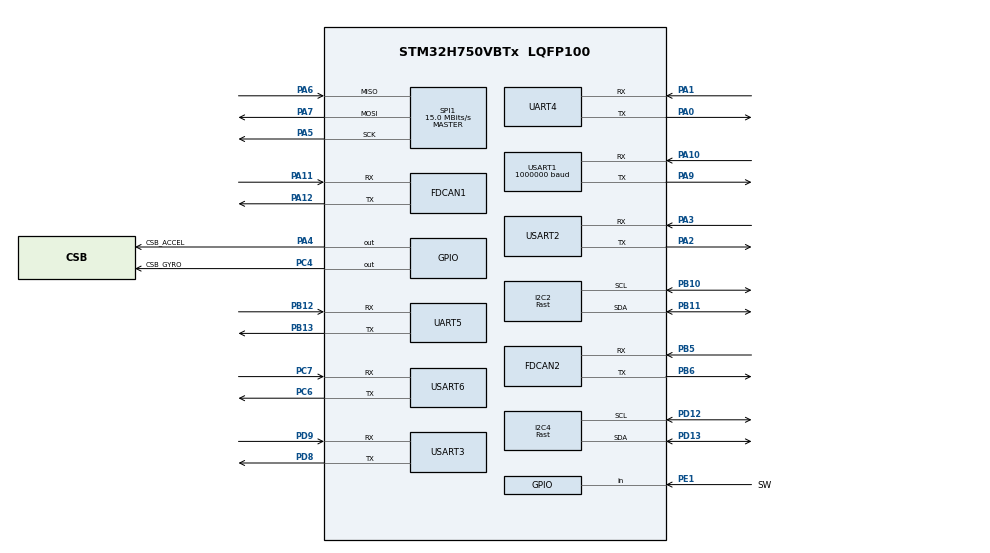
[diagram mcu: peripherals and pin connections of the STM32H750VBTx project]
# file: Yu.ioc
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CORTEX_M7.AccessPermission_Spec=MPU_REGION_FULL_ACCESS
CORTEX_M7.BaseAddress_Spec=0x24000000
CORTEX_M7.CPU_DCache=Enabled
CORTEX_M7.CPU_ICache=Enabled
CORTEX_M7.DisableExec_Spec=MPU_INSTRUCTION_ACCESS_ENABLE
CORTEX_M7.IsCacheable_Spec=MPU_ACCESS_CACHEABLE
CORTEX_M7.IsShareable_Spec=MPU_ACCESS_SHAREABLE
CORTEX_M7.MPU_Control=MPU_HFNMI_PRIVDEF
CORTEX_M7.Size_Spec=MPU_REGION_SIZE_512KB
CORTEX_M7.SubRegionDisable_Spec=0x0
CORTEX_M7.default_mode_Activation=1
Dma.Request0=UART5_RX
Dma.Request1=UART5_TX
Dma.Request10=USART6_TX
Dma.Request11=SPI1_RX
Dma.Request12=SPI1_TX
Dma.Request2=UART4_RX
Dma.Request3=UART4_TX
Dma.Request4=USART2_RX
Dma.Request5=USART2_TX
Dma.Request6=USART1_RX
Dma.Request7=USART3_RX
Dma.Request8=USART3_TX
Dma.Request9=USART6_RX
Dma.SPI1_RX.11.Direction=DMA_PERIPH_TO_MEMORY
Dma.SPI1_RX.11.EventEnable=DISABLE
Dma.SPI1_RX.11.FIFOMode=DMA_FIFOMODE_DISABLE
Dma.SPI1_RX.11.Instance=DMA2_Stream3
Dma.SPI1_RX.11.MemDataAlignment=DMA_MDATAALIGN_BYTE
Dma.SPI1_RX.11.MemInc=DMA_MINC_ENABLE
Dma.SPI1_RX.11.Mode=DMA_NORMAL
Dma.SPI1_RX.11.PeriphDataAlignment=DMA_PDATAALIGN_BYTE
Dma.SPI1_RX.11.PeriphInc=DMA_PINC_DISABLE
Dma.SPI1_RX.11.Polarity=HAL_DMAMUX_REQ_GEN_RISING
Dma.SPI1_RX.11.Priority=DMA_PRIORITY_LOW
Dma.SPI1_RX.11.RequestNumber=1
Dma.SPI1_RX.11.SignalID=NONE
Dma.SPI1_RX.11.SyncEnable=DISABLE
Dma.SPI1_RX.11.SyncPolarity=HAL_DMAMUX_SYNC_NO_EVENT
Dma.SPI1_RX.11.SyncRequestNumber=1
Dma.SPI1_RX.11.SyncSignalID=NONE
Dma.SPI1_TX.12.Direction=DMA_MEMORY_TO_PERIPH
Dma.SPI1_TX.12.EventEnable=DISABLE
Dma.SPI1_TX.12.FIFOMode=DMA_FIFOMODE_DISABLE
Dma.SPI1_TX.12.Instance=DMA2_Stream4
Dma.SPI1_TX.12.MemDataAlignment=DMA_MDATAALIGN_BYTE
Dma.SPI1_TX.12.MemInc=DMA_MINC_ENABLE
Dma.SPI1_TX.12.Mode=DMA_NORMAL
Dma.SPI1_TX.12.PeriphDataAlignment=DMA_PDATAALIGN_BYTE
Dma.SPI1_TX.12.PeriphInc=DMA_PINC_DISABLE
Dma.SPI1_TX.12.Polarity=HAL_DMAMUX_REQ_GEN_RISING
Dma.SPI1_TX.12.Priority=DMA_PRIORITY_LOW
Dma.SPI1_TX.12.RequestNumber=1
Dma.SPI1_TX.12.SignalID=NONE
Dma.SPI1_TX.12.SyncEnable=DISABLE
Dma.SPI1_TX.12.SyncPolarity=HAL_DMAMUX_SYNC_NO_EVENT
Dma.SPI1_TX.12.SyncRequestNumber=1
Dma.SPI1_TX.12.SyncSignalID=NONE
Dma.UART4_RX.2.Direction=DMA_PERIPH_TO_MEMORY
Dma.UART4_RX.2.EventEnable=DISABLE
Dma.UART4_RX.2.FIFOMode=DMA_FIFOMODE_DISABLE
Dma.UART4_RX.2.Instance=DMA1_Stream2
Dma.UART4_RX.2.MemDataAlignment=DMA_MDATAALIGN_BYTE
Dma.UART4_RX.2.MemInc=DMA_MINC_ENABLE
Dma.UART4_RX.2.Mode=DMA_NORMAL
Dma.UART4_RX.2.PeriphDataAlignment=DMA_PDATAALIGN_BYTE
Dma.UART4_RX.2.PeriphInc=DMA_PINC_DISABLE
Dma.UART4_RX.2.Polarity=HAL_DMAMUX_REQ_GEN_RISING
Dma.UART4_RX.2.Priority=DMA_PRIORITY_LOW
Dma.UART4_RX.2.RequestNumber=1
Dma.UART4_RX.2.SignalID=NONE
Dma.UART4_RX.2.SyncEnable=DISABLE
Dma.UART4_RX.2.SyncPolarity=HAL_DMAMUX_SYNC_NO_EVENT
Dma.UART4_RX.2.SyncRequestNumber=1
Dma.UART4_RX.2.SyncSignalID=NONE
Dma.UART4_TX.3.Direction=DMA_MEMORY_TO_PERIPH
Dma.UART4_TX.3.EventEnable=DISABLE
Dma.UART4_TX.3.FIFOMode=DMA_FIFOMODE_DISABLE
Dma.UART4_TX.3.Instance=DMA1_Stream3
Dma.UART4_TX.3.MemDataAlignment=DMA_MDATAALIGN_BYTE
Dma.UART4_TX.3.MemInc=DMA_MINC_ENABLE
Dma.UART4_TX.3.Mode=DMA_NORMAL
Dma.UART4_TX.3.PeriphDataAlignment=DMA_PDATAALIGN_BYTE
Dma.UART4_TX.3.PeriphInc=DMA_PINC_DISABLE
Dma.UART4_TX.3.Polarity=HAL_DMAMUX_REQ_GEN_RISING
Dma.UART4_TX.3.Priority=DMA_PRIORITY_LOW
Dma.UART4_TX.3.RequestNumber=1
Dma.UART4_TX.3.SignalID=NONE
Dma.UART4_TX.3.SyncEnable=DISABLE
Dma.UART4_TX.3.SyncPolarity=HAL_DMAMUX_SYNC_NO_EVENT
Dma.UART4_TX.3.SyncRequestNumber=1
Dma.UART4_TX.3.SyncSignalID=NONE
Dma.UART5_RX.0.Direction=DMA_PERIPH_TO_MEMORY
Dma.UART5_RX.0.EventEnable=DISABLE
Dma.UART5_RX.0.FIFOMode=DMA_FIFOMODE_DISABLE
Dma.UART5_RX.0.Instance=DMA1_Stream0
Dma.UART5_RX.0.MemDataAlignment=DMA_MDATAALIGN_BYTE
Dma.UART5_RX.0.MemInc=DMA_MINC_ENABLE
Dma.UART5_RX.0.Mode=DMA_NORMAL
Dma.UART5_RX.0.PeriphDataAlignment=DMA_PDATAALIGN_BYTE
Dma.UART5_RX.0.PeriphInc=DMA_PINC_DISABLE
Dma.UART5_RX.0.Polarity=HAL_DMAMUX_REQ_GEN_RISING
Dma.UART5_RX.0.Priority=DMA_PRIORITY_LOW
Dma.UART5_RX.0.RequestNumber=1
Dma.UART5_RX.0.SignalID=NONE
Dma.UART5_RX.0.SyncEnable=DISABLE
Dma.UART5_RX.0.SyncPolarity=HAL_DMAMUX_SYNC_NO_EVENT
Dma.UART5_RX.0.SyncRequestNumber=1
Dma.UART5_RX.0.SyncSignalID=NONE
Dma.UART5_TX.1.Direction=DMA_MEMORY_TO_PERIPH
Dma.UART5_TX.1.EventEnable=DISABLE
Dma.UART5_TX.1.FIFOMode=DMA_FIFOMODE_DISABLE
Dma.UART5_TX.1.Instance=DMA1_Stream1
Dma.UART5_TX.1.MemDataAlignment=DMA_MDATAALIGN_BYTE
Dma.UART5_TX.1.MemInc=DMA_MINC_ENABLE
Dma.UART5_TX.1.Mode=DMA_NORMAL
Dma.UART5_TX.1.PeriphDataAlignment=DMA_PDATAALIGN_BYTE
Dma.UART5_TX.1.PeriphInc=DMA_PINC_DISABLE
Dma.UART5_TX.1.Polarity=HAL_DMAMUX_REQ_GEN_RISING
Dma.UART5_TX.1.Priority=DMA_PRIORITY_LOW
Dma.UART5_TX.1.RequestNumber=1
Dma.UART5_TX.1.SignalID=NONE
Dma.UART5_TX.1.SyncEnable=DISABLE
Dma.UART5_TX.1.SyncPolarity=HAL_DMAMUX_SYNC_NO_EVENT
Dma.UART5_TX.1.SyncRequestNumber=1
Dma.UART5_TX.1.SyncSignalID=NONE
Dma.USART1_RX.6.Direction=DMA_PERIPH_TO_MEMORY
Dma.USART1_RX.6.EventEnable=DISABLE
Dma.USART1_RX.6.FIFOMode=DMA_FIFOMODE_DISABLE
Dma.USART1_RX.6.Instance=DMA1_Stream6
Dma.USART1_RX.6.MemDataAlignment=DMA_MDATAALIGN_BYTE
Dma.USART1_RX.6.MemInc=DMA_MINC_ENABLE
Dma.USART1_RX.6.Mode=DMA_NORMAL
Dma.USART1_RX.6.PeriphDataAlignment=DMA_PDATAALIGN_BYTE
Dma.USART1_RX.6.PeriphInc=DMA_PINC_DISABLE
Dma.USART1_RX.6.Polarity=HAL_DMAMUX_REQ_GEN_RISING
Dma.USART1_RX.6.Priority=DMA_PRIORITY_LOW
Dma.USART1_RX.6.RequestNumber=1
Dma.USART1_RX.6.SignalID=NONE
Dma.USART1_RX.6.SyncEnable=DISABLE
Dma.USART1_RX.6.SyncPolarity=HAL_DMAMUX_SYNC_NO_EVENT
Dma.USART1_RX.6.SyncRequestNumber=1
Dma.USART1_RX.6.SyncSignalID=NONE
Dma.USART2_RX.4.Direction=DMA_PERIPH_TO_MEMORY
Dma.USART2_RX.4.EventEnable=DISABLE
Dma.USART2_RX.4.FIFOMode=DMA_FIFOMODE_DISABLE
Dma.USART2_RX.4.Instance=DMA1_Stream4
Dma.USART2_RX.4.MemDataAlignment=DMA_MDATAALIGN_BYTE
Dma.USART2_RX.4.MemInc=DMA_MINC_ENABLE
Dma.USART2_RX.4.Mode=DMA_NORMAL
Dma.USART2_RX.4.PeriphDataAlignment=DMA_PDATAALIGN_BYTE
Dma.USART2_RX.4.PeriphInc=DMA_PINC_DISABLE
Dma.USART2_RX.4.Polarity=HAL_DMAMUX_REQ_GEN_RISING
Dma.USART2_RX.4.Priority=DMA_PRIORITY_LOW
Dma.USART2_RX.4.RequestNumber=1
Dma.USART2_RX.4.SignalID=NONE
Dma.USART2_RX.4.SyncEnable=DISABLE
Dma.USART2_RX.4.SyncPolarity=HAL_DMAMUX_SYNC_NO_EVENT
Dma.USART2_RX.4.SyncRequestNumber=1
Dma.USART2_RX.4.SyncSignalID=NONE
Dma.USART2_TX.5.Direction=DMA_MEMORY_TO_PERIPH
Dma.USART2_TX.5.EventEnable=DISABLE
Dma.USART2_TX.5.FIFOMode=DMA_FIFOMODE_DISABLE
Dma.USART2_TX.5.Instance=DMA1_Stream5
Dma.USART2_TX.5.MemDataAlignment=DMA_MDATAALIGN_BYTE
Dma.USART2_TX.5.MemInc=DMA_MINC_ENABLE
Dma.USART2_TX.5.Mode=DMA_NORMAL
Dma.USART2_TX.5.PeriphDataAlignment=DMA_PDATAALIGN_BYTE
Dma.USART2_TX.5.PeriphInc=DMA_PINC_DISABLE
Dma.USART2_TX.5.Polarity=HAL_DMAMUX_REQ_GEN_RISING
Dma.USART2_TX.5.Priority=DMA_PRIORITY_LOW
Dma.USART2_TX.5.RequestNumber=1
Dma.USART2_TX.5.SignalID=NONE
Dma.USART2_TX.5.SyncEnable=DISABLE
Dma.USART2_TX.5.SyncPolarity=HAL_DMAMUX_SYNC_NO_EVENT
Dma.USART2_TX.5.SyncRequestNumber=1
Dma.USART2_TX.5.SyncSignalID=NONE
Dma.USART3_RX.7.Direction=DMA_PERIPH_TO_MEMORY
Dma.USART3_RX.7.EventEnable=DISABLE
Dma.USART3_RX.7.FIFOMode=DMA_FIFOMODE_DISABLE
Dma.USART3_RX.7.Instance=DMA1_Stream7
Dma.USART3_RX.7.MemDataAlignment=DMA_MDATAALIGN_BYTE
Dma.USART3_RX.7.MemInc=DMA_MINC_ENABLE
Dma.USART3_RX.7.Mode=DMA_NORMAL
Dma.USART3_RX.7.PeriphDataAlignment=DMA_PDATAALIGN_BYTE
Dma.USART3_RX.7.PeriphInc=DMA_PINC_DISABLE
Dma.USART3_RX.7.Polarity=HAL_DMAMUX_REQ_GEN_RISING
Dma.USART3_RX.7.Priority=DMA_PRIORITY_LOW
Dma.USART3_RX.7.RequestNumber=1
Dma.USART3_RX.7.SignalID=NONE
Dma.USART3_RX.7.SyncEnable=DISABLE
Dma.USART3_RX.7.SyncPolarity=HAL_DMAMUX_SYNC_NO_EVENT
Dma.USART3_RX.7.SyncRequestNumber=1
Dma.USART3_RX.7.SyncSignalID=NONE
Dma.USART3_TX.8.Direction=DMA_MEMORY_TO_PERIPH
Dma.USART3_TX.8.EventEnable=DISABLE
Dma.USART3_TX.8.FIFOMode=DMA_FIFOMODE_DISABLE
Dma.USART3_TX.8.Instance=DMA2_Stream0
Dma.USART3_TX.8.MemDataAlignment=DMA_MDATAALIGN_BYTE
Dma.USART3_TX.8.MemInc=DMA_MINC_ENABLE
Dma.USART3_TX.8.Mode=DMA_NORMAL
Dma.USART3_TX.8.PeriphDataAlignment=DMA_PDATAALIGN_BYTE
Dma.USART3_TX.8.PeriphInc=DMA_PINC_DISABLE
Dma.USART3_TX.8.Polarity=HAL_DMAMUX_REQ_GEN_RISING
Dma.USART3_TX.8.Priority=DMA_PRIORITY_LOW
Dma.USART3_TX.8.RequestNumber=1
Dma.USART3_TX.8.SignalID=NONE
Dma.USART3_TX.8.SyncEnable=DISABLE
Dma.USART3_TX.8.SyncPolarity=HAL_DMAMUX_SYNC_NO_EVENT
Dma.USART3_TX.8.SyncRequestNumber=1
Dma.USART3_TX.8.SyncSignalID=NONE
Dma.USART6_RX.9.Direction=DMA_PERIPH_TO_MEMORY
Dma.USART6_RX.9.EventEnable=DISABLE
Dma.USART6_RX.9.FIFOMode=DMA_FIFOMODE_DISABLE
Dma.USART6_RX.9.Instance=DMA2_Stream1
Dma.USART6_RX.9.MemDataAlignment=DMA_MDATAALIGN_BYTE
Dma.USART6_RX.9.MemInc=DMA_MINC_ENABLE
Dma.USART6_RX.9.Mode=DMA_NORMAL
Dma.USART6_RX.9.PeriphDataAlignment=DMA_PDATAALIGN_BYTE
Dma.USART6_RX.9.PeriphInc=DMA_PINC_DISABLE
Dma.USART6_RX.9.Polarity=HAL_DMAMUX_REQ_GEN_RISING
Dma.USART6_RX.9.Priority=DMA_PRIORITY_LOW
Dma.USART6_RX.9.RequestNumber=1
Dma.USART6_RX.9.SignalID=NONE
Dma.USART6_RX.9.SyncEnable=DISABLE
Dma.USART6_RX.9.SyncPolarity=HAL_DMAMUX_SYNC_NO_EVENT
Dma.USART6_RX.9.SyncRequestNumber=1
Dma.USART6_RX.9.SyncSignalID=NONE
Dma.USART6_TX.10.Direction=DMA_MEMORY_TO_PERIPH
Dma.USART6_TX.10.EventEnable=DISABLE
Dma.USART6_TX.10.FIFOMode=DMA_FIFOMODE_DISABLE
Dma.USART6_TX.10.Instance=DMA2_Stream2
Dma.USART6_TX.10.MemDataAlignment=DMA_MDATAALIGN_BYTE
Dma.USART6_TX.10.MemInc=DMA_MINC_ENABLE
Dma.USART6_TX.10.Mode=DMA_NORMAL
Dma.USART6_TX.10.PeriphDataAlignment=DMA_PDATAALIGN_BYTE
Dma.USART6_TX.10.PeriphInc=DMA_PINC_DISABLE
Dma.USART6_TX.10.Polarity=HAL_DMAMUX_REQ_GEN_RISING
Dma.USART6_TX.10.Priority=DMA_PRIORITY_LOW
Dma.USART6_TX.10.RequestNumber=1
Dma.USART6_TX.10.SignalID=NONE
Dma.USART6_TX.10.SyncEnable=DISABLE
Dma.USART6_TX.10.SyncPolarity=HAL_DMAMUX_SYNC_NO_EVENT
Dma.USART6_TX.10.SyncRequestNumber=1
Dma.USART6_TX.10.SyncSignalID=NONE
FDCAN1.CalculateBaudRateNominal=1000000
FDCAN1.CalculateTimeBitNominal=1000
FDCAN1.CalculateTimeQuantumNominal=25.0
FDCAN1.DataPrescaler=3
FDCAN1.DataSyncJumpWidth=10
FDCAN1.DataTimeSeg1=29
FDCAN1.DataTimeSeg2=10
FDCAN1.NominalPrescaler=3
FDCAN1.NominalSyncJumpWidth=10
FDCAN1.NominalTimeSeg1=29
FDCAN1.NominalTimeSeg2=10
FDCAN1.ProtocolException=ENABLE
FDCAN1.RxFifo0ElmtsNbr=2
FDCAN1.StdFiltersNbr=1
FDCAN1.TxFifoQueueElmtsNbr=4
FDCAN2.CalculateBaudRateNominal=1000000
FDCAN2.CalculateTimeBitNominal=1000
FDCAN2.CalculateTimeQuantumNominal=25.0
FDCAN2.DataPrescaler=3
FDCAN2.DataSyncJumpWidth=10
FDCAN2.DataTimeSeg1=29
FDCAN2.DataTimeSeg2=10
FDCAN2.MessageRAMOffset=1280
FDCAN2.NominalPrescaler=3
FDCAN2.NominalSyncJumpWidth=10
FDCAN2.NominalTimeSeg1=29
FDCAN2.NominalTimeSeg2=10
FDCAN2.ProtocolException=ENABLE
FDCAN2.RxFifo0ElmtsNbr=2
FDCAN2.StdFiltersNbr=1
FDCAN2.TxFifoQueueElmtsNbr=4
FREERTOS.Tasks01=defaultTask,8,128,StartDefaultTask,Default,NULL,Dynamic,NULL,NULL
FREERTOS.configENABLE_FPU=1
I2C2.I2C_Speed_Mode=I2C_Fast
I2C2.Timing=0x00B03FDB
I2C4.I2C_Speed_Mode=I2C_Fast
I2C4.Timing=0x00B03FDB
Mcu.Family=STM32H7
Mcu.Name=STM32H750VBTx
Mcu.Package=LQFP100
NVIC.DMA1_Stream0_IRQn=true\:5\:0\:false\:false\:true\:true\:false\:true\:true
NVIC.DMA1_Stream1_IRQn=true\:5\:0\:false\:false\:true\:true\:false\:true\:true
NVIC.DMA1_Stream2_IRQn=true\:5\:0\:false\:false\:true\:true\:false\:true\:true
NVIC.DMA1_Stream3_IRQn=true\:5\:0\:false\:false\:true\:true\:false\:true\:true
NVIC.DMA1_Stream4_IRQn=true\:5\:0\:false\:false\:true\:true\:false\:true\:true
NVIC.DMA1_Stream5_IRQn=true\:5\:0\:false\:false\:true\:true\:false\:true\:true
NVIC.DMA1_Stream6_IRQn=true\:5\:0\:false\:false\:true\:true\:false\:true\:true
NVIC.DMA1_Stream7_IRQn=true\:5\:0\:false\:false\:true\:true\:false\:true\:true
NVIC.DMA2_Stream0_IRQn=true\:5\:0\:false\:false\:true\:true\:false\:true\:true
NVIC.DMA2_Stream1_IRQn=true\:5\:0\:false\:false\:true\:true\:false\:true\:true
NVIC.DMA2_Stream2_IRQn=true\:5\:0\:false\:false\:true\:true\:false\:true\:true
NVIC.DMA2_Stream3_IRQn=true\:5\:0\:false\:false\:true\:true\:false\:true\:true
NVIC.DMA2_Stream4_IRQn=true\:5\:0\:false\:false\:true\:true\:false\:true\:true
NVIC.FDCAN1_IT0_IRQn=true\:5\:0\:false\:false\:true\:true\:true\:true\:true
NVIC.PriorityGroup=NVIC_PRIORITYGROUP_4
NVIC.SPI1_IRQn=true\:5\:0\:false\:false\:true\:true\:false\:true\:true
NVIC.TIM1_UP_IRQn=true\:15\:0\:false\:false\:true\:false\:false\:true\:true
NVIC.TimeBase=TIM1_UP_IRQn
NVIC.TimeBaseIP=TIM1
NVIC.UART4_IRQn=true\:5\:0\:false\:false\:true\:true\:true\:true\:true
NVIC.UART5_IRQn=true\:5\:0\:false\:false\:true\:true\:true\:true\:true
NVIC.USART1_IRQn=true\:5\:0\:false\:false\:true\:true\:true\:true\:true
NVIC.USART2_IRQn=true\:5\:0\:false\:false\:true\:true\:true\:true\:true
NVIC.USART3_IRQn=true\:5\:0\:false\:false\:true\:true\:true\:true\:true
NVIC.USART6_IRQn=true\:5\:0\:false\:false\:true\:true\:true\:true\:true
PA0.Mode=Asynchronous
PA0.Signal=UART4_TX
PA1.Mode=Asynchronous
PA1.Signal=UART4_RX
PA10.Mode=Asynchronous
PA10.Signal=USART1_RX
PA11.Mode=FDCAN_Activate
PA11.Signal=FDCAN1_RX
PA12.Mode=FDCAN_Activate
PA12.Signal=FDCAN1_TX
PA13\ (JTMS/SWDIO).Mode=Serial_Wire
PA13\ (JTMS/SWDIO).Signal=DEBUG_JTMS-SWDIO
PA14\ (JTCK/SWCLK).Mode=Serial_Wire
PA14\ (JTCK/SWCLK).Signal=DEBUG_JTCK-SWCLK
PA2.Mode=Asynchronous
PA2.Signal=USART2_TX
PA3.Mode=Asynchronous
PA3.Signal=USART2_RX
PA4.GPIO_Label=CSB_ACCEL
PA4.GPIO_PuPd=GPIO_PULLUP
PA4.GPIO_Speed=GPIO_SPEED_FREQ_HIGH
PA4.PinState=GPIO_PIN_SET
PA4.Signal=GPIO_Output
PA5.GPIO_Speed=GPIO_SPEED_FREQ_VERY_HIGH
PA5.Mode=Full_Duplex_Master
PA5.Signal=SPI1_SCK
PA6.GPIO_PuPd=GPIO_PULLUP
PA6.GPIO_Speed=GPIO_SPEED_FREQ_VERY_HIGH
PA6.Mode=Full_Duplex_Master
PA6.Signal=SPI1_MISO
PA7.GPIO_PuPd=GPIO_PULLUP
PA7.GPIO_Speed=GPIO_SPEED_FREQ_VERY_HIGH
PA7.Mode=Full_Duplex_Master
PA7.Signal=SPI1_MOSI
PA9.Mode=Asynchronous
PA9.Signal=USART1_TX
PB10.Mode=I2C
PB10.Signal=I2C2_SCL
PB11.Mode=I2C
PB11.Signal=I2C2_SDA
PB12.Mode=Asynchronous
PB12.Signal=UART5_RX
PB13.Mode=Asynchronous
PB13.Signal=UART5_TX
PB5.Mode=FDCAN_Activate
PB5.Signal=FDCAN2_RX
PB6.Mode=FDCAN_Activate
PB6.Signal=FDCAN2_TX
PC4.GPIO_Label=CSB_GYRO
PC4.GPIO_PuPd=GPIO_PULLUP
PC4.GPIO_Speed=GPIO_SPEED_FREQ_HIGH
PC4.PinState=GPIO_PIN_SET
PC4.Signal=GPIO_Output
PC6.Mode=Asynchronous
PC6.Signal=USART6_TX
PC7.Mode=Asynchronous
PC7.Signal=USART6_RX
PD12.Mode=I2C
PD12.Signal=I2C4_SCL
PD13.Mode=I2C
PD13.Signal=I2C4_SDA
PD8.Mode=Asynchronous
PD8.Signal=USART3_TX
PD9.Mode=Asynchronous
PD9.Signal=USART3_RX
PE1.GPIO_Label=SW
PE1.Signal=GPIO_Input
PH0-OSC_IN\ (PH0).Mode=HSE-External-Oscillator
PH0-OSC_IN\ (PH0).Signal=RCC_OSC_IN
PH1-OSC_OUT\ (PH1).Mode=HSE-External-Oscillator
PH1-OSC_OUT\ (PH1).Signal=RCC_OSC_OUT
ProjectManager.HeapSize=0x200
ProjectManager.StackSize=0x400
ProjectManager.TargetToolchain=CMake
RCC.ADCFreq_Value=16125000
RCC.APB1Freq_Value=120000000
RCC.APB2Freq_Value=120000000
RCC.APB3Freq_Value=120000000
RCC.APB4Freq_Value=120000000
RCC.CortexFreq_Value=480000000
RCC.D1PPRE=RCC_APB3_DIV2
RCC.D2PPRE1=RCC_APB1_DIV2
RCC.D2PPRE2=RCC_APB2_DIV2
RCC.D3PPRE=RCC_APB4_DIV2
RCC.DIVM1=1
RCC.DIVN1=120
RCC.DIVQ1=8
RCC.HCLKFreq_Value=240000000
RCC.HPRE=RCC_HCLK_DIV2
RCC.HSE_VALUE=8000000
RCC.PLL2FRACN=0
RCC.PLL3FRACN=0
RCC.PLLFRACN=0
RCC.PLLSourceVirtual=RCC_PLLSOURCE_HSE
RCC.SYSCLKFreq_VALUE=480000000
RCC.SYSCLKSource=RCC_SYSCLKSOURCE_PLLCLK
RCC.USBFreq_Value=120000000
SPI1.BaudRatePrescaler=SPI_BAUDRATEPRESCALER_8
SPI1.CalculateBaudRate=15.0 MBits/s
SPI1.DataSize=SPI_DATASIZE_8BIT
SPI1.Direction=SPI_DIRECTION_2LINES
SPI1.Mode=SPI_MODE_MASTER
SPI1.VirtualType=VM_MASTER
USART1.BaudRate=1000000
USART1.Parity=PARITY_EVEN
USART1.VirtualMode-Asynchronous=VM_ASYNC
USART1.WordLength=WORDLENGTH_9B
USART2.VirtualMode-Asynchronous=VM_ASYNC
USART3.VirtualMode-Asynchronous=VM_ASYNC
USART6.VirtualMode=VM_ASYNC
VP_FREERTOS_VS_CMSIS_V2.Mode=CMSIS_V2
VP_MEMORYMAP_VS_MEMORYMAP.Mode=CurAppReg
VP_SYS_VS_tim1.Mode=TIM1
board=custom

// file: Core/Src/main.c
/* USER CODE BEGIN Header */
/**
  ******************************************************************************
  * @file           : main.c
  * @brief          : Main program body
  ******************************************************************************
  * @attention
  *
  * Copyright (c) 2025 STMicroelectronics.
  * All rights reserved.
  *
  * This software is licensed under terms that can be found in the LICENSE file
  * in the root directory of this software component.
  * If no LICENSE file comes with this software, it is provided AS-IS.
  *
  ******************************************************************************
  */
/* USER CODE END Header */
#include "main.h"
#include "cmsis_os.h"
#include "dma.h"
#include "fdcan.h"
#include "i2c.h"
#include "memorymap.h"
#include "spi.h"
#include "usart.h"
#include "gpio.h"

void SystemClock_Config(void);
static void MPU_Config(void);
void MX_FREERTOS_Init(void);

int main(void)
{

  /* MPU Configuration--------------------------------------------------------*/
  MPU_Config();

  /* Enable the CPU Cache */

  /* Enable I-Cache---------------------------------------------------------*/
  SCB_EnableICache();

  /* Enable D-Cache---------------------------------------------------------*/
  SCB_EnableDCache();

  /* MCU Configuration--------------------------------------------------------*/

  /* Reset of all peripherals, Initializes the Flash interface and the Systick. */
  HAL_Init();

  /* Configure the system clock */
  SystemClock_Config();

  /* USER CODE BEGIN SysInit */
  SCB->CPACR |= ((3UL << (10 * 2)) | (3UL << (11 * 2)));
  /* USER CODE END SysInit */

  /* Initialize all configured peripherals */
  MX_GPIO_Init();
  MX_DMA_Init();
  MX_UART5_Init();
  MX_FDCAN1_Init();
  MX_FDCAN2_Init();
  MX_UART4_Init();
  MX_USART2_UART_Init();
  MX_USART1_UART_Init();
  MX_USART3_UART_Init();
  MX_USART6_UART_Init();
  MX_SPI1_Init();
  MX_I2C2_Init();
  MX_I2C4_Init();

  /* Init scheduler */
  osKernelInitialize();

  /* Call init function for freertos objects (in cmsis_os2.c) */
  MX_FREERTOS_Init();

  /* Start scheduler */
  osKernelStart();

  /* We should never get here as control is now taken by the scheduler */

  /* Infinite loop */
  while (1)
  {

  }
}

void SystemClock_Config(void)
{
  RCC_OscInitTypeDef RCC_OscInitStruct = {0};
  RCC_ClkInitTypeDef RCC_ClkInitStruct = {0};

  /** Supply configuration update enable
  */
  HAL_PWREx_ConfigSupply(PWR_LDO_SUPPLY);

  /** Configure the main internal regulator output voltage
  */
  __HAL_PWR_VOLTAGESCALING_CONFIG(PWR_REGULATOR_VOLTAGE_SCALE1);

  while(!__HAL_PWR_GET_FLAG(PWR_FLAG_VOSRDY)) {}

  __HAL_RCC_SYSCFG_CLK_ENABLE();
  __HAL_PWR_VOLTAGESCALING_CONFIG(PWR_REGULATOR_VOLTAGE_SCALE0);

  while(!__HAL_PWR_GET_FLAG(PWR_FLAG_VOSRDY)) {}

  /** Initializes the RCC Oscillators according to the specified parameters
  * in the RCC_OscInitTypeDef structure.
  */
  RCC_OscInitStruct.OscillatorType = RCC_OSCILLATORTYPE_HSE;
  RCC_OscInitStruct.HSEState = RCC_HSE_ON;
  RCC_OscInitStruct.PLL.PLLState = RCC_PLL_ON;
  RCC_OscInitStruct.PLL.PLLSource = RCC_PLLSOURCE_HSE;
  RCC_OscInitStruct.PLL.PLLM = 1;
  RCC_OscInitStruct.PLL.PLLN = 120;
  RCC_OscInitStruct.PLL.PLLP = 2;
  RCC_OscInitStruct.PLL.PLLQ = 8;
  RCC_OscInitStruct.PLL.PLLR = 2;
  RCC_OscInitStruct.PLL.PLLRGE = RCC_PLL1VCIRANGE_3;
  RCC_OscInitStruct.PLL.PLLVCOSEL = RCC_PLL1VCOWIDE;
  RCC_OscInitStruct.PLL.PLLFRACN = 0;
  if (HAL_RCC_OscConfig(&RCC_OscInitStruct) != HAL_OK)
  {
    Error_Handler();
  }

  /** Initializes the CPU, AHB and APB buses clocks
  */
  RCC_ClkInitStruct.ClockType = RCC_CLOCKTYPE_HCLK|RCC_CLOCKTYPE_SYSCLK
                              |RCC_CLOCKTYPE_PCLK1|RCC_CLOCKTYPE_PCLK2
                              |RCC_CLOCKTYPE_D3PCLK1|RCC_CLOCKTYPE_D1PCLK1;
  RCC_ClkInitStruct.SYSCLKSource = RCC_SYSCLKSOURCE_PLLCLK;
  RCC_ClkInitStruct.SYSCLKDivider = RCC_SYSCLK_DIV1;
  RCC_ClkInitStruct.AHBCLKDivider = RCC_HCLK_DIV2;
  RCC_ClkInitStruct.APB3CLKDivider = RCC_APB3_DIV2;
  RCC_ClkInitStruct.APB1CLKDivider = RCC_APB1_DIV2;
  RCC_ClkInitStruct.APB2CLKDivider = RCC_APB2_DIV2;
  RCC_ClkInitStruct.APB4CLKDivider = RCC_APB4_DIV2;

  if (HAL_RCC_ClockConfig(&RCC_ClkInitStruct, FLASH_LATENCY_4) != HAL_OK)
  {
    Error_Handler();
  }
}

 /* MPU Configuration */

void MPU_Config(void)
{
  MPU_Region_InitTypeDef MPU_InitStruct = {0};

  /* Disables the MPU */
  HAL_MPU_Disable();

  /** Initializes and configures the Region and the memory to be protected
  */
  MPU_InitStruct.Enable = MPU_REGION_ENABLE;
  MPU_InitStruct.Number = MPU_REGION_NUMBER0;
  MPU_InitStruct.BaseAddress = 0x24000000;
  MPU_InitStruct.Size = MPU_REGION_SIZE_512KB;
  MPU_InitStruct.SubRegionDisable = 0x0;
  MPU_InitStruct.TypeExtField = MPU_TEX_LEVEL0;
  MPU_InitStruct.AccessPermission = MPU_REGION_FULL_ACCESS;
  MPU_InitStruct.DisableExec = MPU_INSTRUCTION_ACCESS_ENABLE;
  MPU_InitStruct.IsShareable = MPU_ACCESS_SHAREABLE;
  MPU_InitStruct.IsCacheable = MPU_ACCESS_CACHEABLE;
  MPU_InitStruct.IsBufferable = MPU_ACCESS_NOT_BUFFERABLE;

  HAL_MPU_ConfigRegion(&MPU_InitStruct);
  /* Enables the MPU */
  HAL_MPU_Enable(MPU_HFNMI_PRIVDEF);

}

void HAL_TIM_PeriodElapsedCallback(TIM_HandleTypeDef *htim)
{
  if (htim->Instance == TIM1) {
    HAL_IncTick();
  }
}

void Error_Handler(void)
{
  __disable_irq();
  while (1)
  {
  }
}

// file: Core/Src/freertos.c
/* USER CODE BEGIN Header */
/**
  ******************************************************************************
  * File Name          : freertos.c
  * Description        : Code for freertos applications
  ******************************************************************************
  * @attention
  *
  * Copyright (c) 2025 STMicroelectronics.
  * All rights reserved.
  *
  * This software is licensed under terms that can be found in the LICENSE file
  * in the root directory of this software component.
  * If no LICENSE file comes with this software, it is provided AS-IS.
  *
  ******************************************************************************
  */
/* USER CODE END Header */

#include "FreeRTOS.h"
#include "task.h"
#include "main.h"
#include "cmsis_os.h"

/* USER CODE BEGIN Includes */
#include "init_task.h"
/* USER CODE END Includes */

/* Definitions for defaultTask */
osThreadId_t defaultTaskHandle;
const osThreadAttr_t defaultTask_attributes = {
  .name = "defaultTask",
  .stack_size = 128 * 4,
  .priority = (osPriority_t) osPriorityLow,
};

void StartDefaultTask(void *argument);

void MX_FREERTOS_Init(void); /* (MISRA C 2004 rule 8.1) */

void MX_FREERTOS_Init(void) {

  /* Create the thread(s) */
  /* creation of defaultTask */
  defaultTaskHandle = osThreadNew(StartDefaultTask, NULL, &defaultTask_attributes);

  /* USER CODE BEGIN RTOS_EVENTS */
  /* add events, ... */
  xTaskCreate(Init_Task, "Init_Task", 256, NULL, osPriorityISR, NULL);
  /* USER CODE END RTOS_EVENTS */

}

void StartDefaultTask(void *argument)
{
  /* USER CODE BEGIN StartDefaultTask */
  (void)argument; /* 显式标注参数未使用，消除编译警告 */
  vTaskSuspend(NULL);
  /* Infinite loop */
  for(;;)
  {

  }
  /* USER CODE END StartDefaultTask */
}
